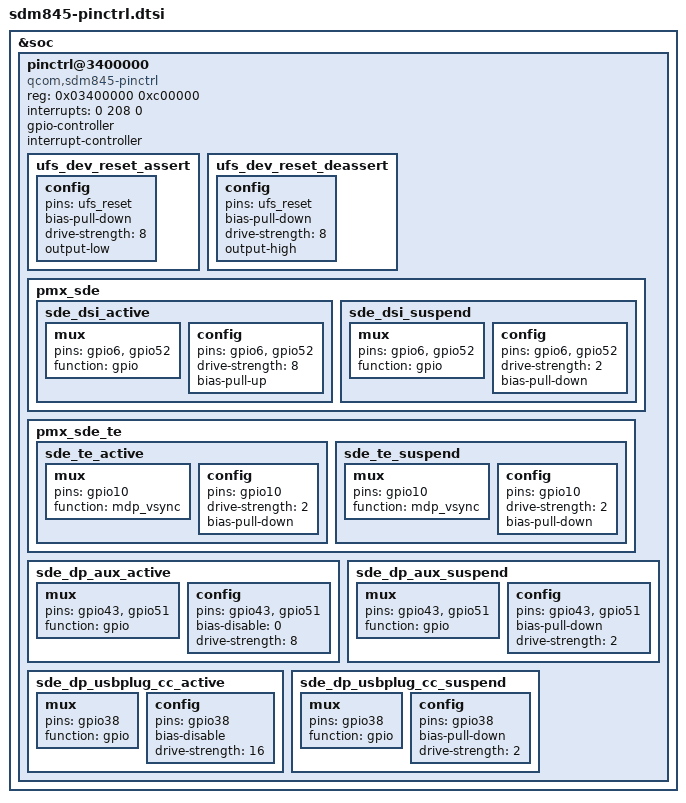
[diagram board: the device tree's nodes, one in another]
/* Copyright (c) 2016-2018, The Linux Foundation. All rights reserved.
 *
 * This program is free software; you can redistribute it and/or modify
 * it under the terms of the GNU General Public License version 2 and
 * only version 2 as published by the Free Software Foundation.
 *
 * This program is distributed in the hope that it will be useful,
 * but WITHOUT ANY WARRANTY; without even the implied warranty of
 * MERCHANTABILITY or FITNESS FOR A PARTICULAR PURPOSE.  See the
 * GNU General Public License for more details.
 */

&soc {
	pinctrl@3400000 {
		compatible = "qcom,sdm845-pinctrl";
		reg = <0x03400000 0xc00000>;
		interrupts = <0 208 0>;
		gpio-controller;
		#gpio-cells = <2>;
		interrupt-controller;
		#interrupt-cells = <2>;

		ufs_dev_reset_assert: ufs_dev_reset_assert {
			config {
				pins = "ufs_reset";
				bias-pull-down;		/* default: pull down */
				/*
				 * UFS_RESET driver strengths are having
				 * different values/steps compared to typical
				 * GPIO drive strengths.
				 *
				 * Following table clarifies:
				 *
				 * HDRV value | UFS_RESET | Typical GPIO
				 *   (dec)    |   (mA)    |    (mA)
				 *     0      |   0.8     |    2
				 *     1      |   1.55    |    4
				 *     2      |   2.35    |    6
				 *     3      |   3.1     |    8
				 *     4      |   3.9     |    10
				 *     5      |   4.65    |    12
				 *     6      |   5.4     |    14
				 *     7      |   6.15    |    16
				 *
				 * POR value for UFS_RESET HDRV is 3 which means
				 * 3.1mA and we want to use that. Hence just
				 * specify 8mA to "drive-strength" binding and
				 * that should result into writing 3 to HDRV
				 * field.
				 */
				drive-strength = <8>;	/* default: 3.1 mA */
				output-low; /* active low reset */
			};
		};

		ufs_dev_reset_deassert: ufs_dev_reset_deassert {
			config {
				pins = "ufs_reset";
				bias-pull-down;		/* default: pull down */
				/*
				 * default: 3.1 mA
				 * check comments under ufs_dev_reset_assert
				 */
				drive-strength = <8>;
				output-high; /* active low reset */
			};
		};

		pmx_sde: pmx_sde {
			sde_dsi_active: sde_dsi_active {
				mux {
					pins = "gpio6", "gpio52";
					function = "gpio";
				};

				config {
					pins = "gpio6", "gpio52";
					drive-strength = <8>;
					bias-pull-up;
					/*bias-disable = <0>;*/
				};
			};
			sde_dsi_suspend: sde_dsi_suspend {
				mux {
					pins = "gpio6", "gpio52";
					function = "gpio";
				};

				config {
					pins = "gpio6", "gpio52";
					drive-strength = <2>;
					bias-pull-down;
				};
			};
		};

		pmx_sde_te {
			sde_te_active: sde_te_active {
				mux {
					pins = "gpio10";
					function = "mdp_vsync";
				};

				config {
					pins = "gpio10";
					drive-strength = <2>;   /* 2 mA */
					bias-pull-down;         /* PULL DOWN */
				};
			};

			sde_te_suspend: sde_te_suspend {
				mux {
					pins = "gpio10";
					function = "mdp_vsync";
				};

				config {
					pins = "gpio10";
					drive-strength = <2>;   /* 2 mA */
					bias-pull-down;         /* PULL DOWN */
				};
			};
		};

		sde_dp_aux_active: sde_dp_aux_active {
			mux {
				pins = "gpio43", "gpio51";
				function = "gpio";
			};

			config {
				pins = "gpio43", "gpio51";
				bias-disable = <0>; /* no pull */
				drive-strength = <8>;
			};
		};

		sde_dp_aux_suspend: sde_dp_aux_suspend {
			mux {
				pins = "gpio43", "gpio51";
				function = "gpio";
			};

			config {
				pins = "gpio43", "gpio51";
				bias-pull-down;
				drive-strength = <2>;
			};
		};

		sde_dp_usbplug_cc_active: sde_dp_usbplug_cc_active {
			mux {
				pins = "gpio38";
				function = "gpio";
			};

			config {
				pins = "gpio38";
				bias-disable;
				drive-strength = <16>;
			};
		};

		sde_dp_usbplug_cc_suspend: sde_dp_usbplug_cc_suspend {
			mux {
				pins = "gpio38";
				function = "gpio";
			};

			config {
				pins = "gpio38";
				bias-pull-down;
				drive-strength = <2>;
			};
		};
	};
};
